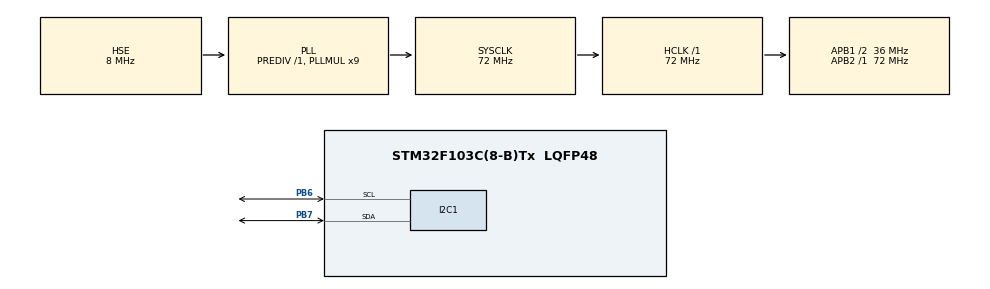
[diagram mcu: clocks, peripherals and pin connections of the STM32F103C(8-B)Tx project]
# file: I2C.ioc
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Mcu.Family=STM32F1
Mcu.Name=STM32F103C(8-B)Tx
Mcu.Package=LQFP48
NVIC.PriorityGroup=NVIC_PRIORITYGROUP_4
PA13.Mode=Serial_Wire
PA13.Signal=SYS_JTMS-SWDIO
PA14.Mode=Serial_Wire
PA14.Signal=SYS_JTCK-SWCLK
PB6.Mode=I2C
PB6.Signal=I2C1_SCL
PB7.Mode=I2C
PB7.Signal=I2C1_SDA
PD0-OSC_IN.Mode=HSE-External-Oscillator
PD0-OSC_IN.Signal=RCC_OSC_IN
PD1-OSC_OUT.Mode=HSE-External-Oscillator
PD1-OSC_OUT.Signal=RCC_OSC_OUT
ProjectManager.HeapSize=0x200
ProjectManager.StackSize=0x400
ProjectManager.TargetToolchain=STM32CubeIDE
RCC.AHBFreq_Value=72000000
RCC.APB1CLKDivider=RCC_HCLK_DIV2
RCC.APB1Freq_Value=36000000
RCC.APB1TimFreq_Value=72000000
RCC.APB2Freq_Value=72000000
RCC.APB2TimFreq_Value=72000000
RCC.HCLKFreq_Value=72000000
RCC.PLLMUL=RCC_PLL_MUL9
RCC.PLLSourceVirtual=RCC_PLLSOURCE_HSE
RCC.SYSCLKFreq_VALUE=72000000
RCC.SYSCLKSource=RCC_SYSCLKSOURCE_PLLCLK
RCC.USBFreq_Value=72000000
board=custom

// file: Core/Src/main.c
/* USER CODE BEGIN Header */
/**
  ******************************************************************************
  * @file           : main.c
  * @brief          : Main program body
  ******************************************************************************
  * @attention
  *
  * Copyright (c) 2025 STMicroelectronics.
  * All rights reserved.
  *
  * This software is licensed under terms that can be found in the LICENSE file
  * in the root directory of this software component.
  * If no LICENSE file comes with this software, it is provided AS-IS.
  *
  ******************************************************************************
  */
/* USER CODE END Header */
#include "main.h"

I2C_HandleTypeDef hi2c1;

void SystemClock_Config(void);
static void MX_GPIO_Init(void);
static void MX_I2C1_Init(void);

/* USER CODE BEGIN 0 */
#define LCD_ADDRESS   (0x27 << 1)
#define LCD_BACKLIGHT 0x08
#define LCD_RS 		  0x01
#define LCD_EN 		  0x04
static void lcd_send_cmd(uint8_t cmd){
	uint8_t data_high, data_low; // tach 4 bit cao 4 bit thap
	uint8_t data_transmit[4];//truyen du lieu 4 bit
	data_high = cmd & 0xF0;
	data_low = (cmd << 4) & 0xF0;

	data_transmit[0] = data_high | LCD_EN | LCD_BACKLIGHT;
	data_transmit[1] = data_high | LCD_BACKLIGHT;
	data_transmit[2] = data_low  | LCD_EN | LCD_BACKLIGHT;
	data_transmit[3] = data_low  | LCD_BACKLIGHT;

	HAL_I2C_Master_Transmit(&hi2c1, LCD_ADDRESS, data_transmit, 4, 100); //bước chốt truyền data xuống lcd
	HAL_Delay(20);
}
static void lcd_send_data(uint8_t data){
	uint8_t data_high, data_low; // tach 4 bit cao 4 bit thap
	uint8_t data_transmit[4];//truyen du lieu 4 bit
	data_high = data & 0xF0;
	data_low = (data << 4) & 0xF0;

	data_transmit[0] = data_high | LCD_EN | LCD_BACKLIGHT | LCD_RS;
	data_transmit[1] = data_high | LCD_BACKLIGHT | LCD_RS;
	data_transmit[2] = data_low  | LCD_EN | LCD_BACKLIGHT | LCD_RS;
	data_transmit[3] = data_low  | LCD_BACKLIGHT | LCD_RS;

	HAL_I2C_Master_Transmit(&hi2c1, LCD_ADDRESS, data_transmit, 4, 100);
	HAL_Delay(20);
}
void lcd_init(){
	HAL_Delay(50);
	lcd_send_cmd(0x30);
	lcd_send_cmd(0x20);
	lcd_send_cmd(0x28);
	lcd_send_cmd(0x08);
	lcd_send_cmd(0x01);
	HAL_Delay(5);
	lcd_send_cmd(0x06);
	lcd_send_cmd(0x0C);
}

void lcd_send_string(char *str){
	while(*str){
		lcd_send_data(*str++);
	}
}
static const uint8_t char_heart[8] = {
	0b00000,
	0b01010,
	0b11111,
	0b11111,
	0b01110,
	0b00100,
	0b00000,
	0b00000
};

void lcd_create_char(uint8_t location, const uint8_t charmap[8]){
	location &=0x07;
	lcd_send_cmd(0x40 | (location << 3));   // set CGRAM addr
		for (uint8_t i = 0; i < 8; i++) {
			lcd_send_data(charmap[i]);
	}
}
static void lcd_set_cursor(uint8_t col, uint8_t row){
    uint8_t addr = (row ? 0x40 : 0x00) + col; // row=0 -> 0x00, row=1 -> 0x40
    lcd_send_cmd(0x80 | addr);                // Set DDRAM address
}

/* USER CODE END 0 */

int main(void)
{

  /* MCU Configuration--------------------------------------------------------*/

  /* Reset of all peripherals, Initializes the Flash interface and the Systick. */
  HAL_Init();

  /* Configure the system clock */
  SystemClock_Config();

  /* Initialize all configured peripherals */
  MX_GPIO_Init();
  MX_I2C1_Init();
  /* USER CODE BEGIN 2 */
  lcd_init();
  lcd_create_char(0, char_heart);
  lcd_set_cursor(0,0);
  //lcd_send_string("kiet an cut");
  lcd_set_cursor(0,1);
  lcd_send_string("I");
  lcd_send_data(0x00);
  lcd_send_string("TikTok");

  /* USER CODE END 2 */

  /* Infinite loop */
  while (1)
  {

  }
}

void SystemClock_Config(void)
{
  RCC_OscInitTypeDef RCC_OscInitStruct = {0};
  RCC_ClkInitTypeDef RCC_ClkInitStruct = {0};

  /** Initializes the RCC Oscillators according to the specified parameters
  * in the RCC_OscInitTypeDef structure.
  */
  RCC_OscInitStruct.OscillatorType = RCC_OSCILLATORTYPE_HSE;
  RCC_OscInitStruct.HSEState = RCC_HSE_ON;
  RCC_OscInitStruct.HSEPredivValue = RCC_HSE_PREDIV_DIV1;
  RCC_OscInitStruct.HSIState = RCC_HSI_ON;
  RCC_OscInitStruct.PLL.PLLState = RCC_PLL_ON;
  RCC_OscInitStruct.PLL.PLLSource = RCC_PLLSOURCE_HSE;
  RCC_OscInitStruct.PLL.PLLMUL = RCC_PLL_MUL9;
  if (HAL_RCC_OscConfig(&RCC_OscInitStruct) != HAL_OK)
  {
    Error_Handler();
  }

  /** Initializes the CPU, AHB and APB buses clocks
  */
  RCC_ClkInitStruct.ClockType = RCC_CLOCKTYPE_HCLK|RCC_CLOCKTYPE_SYSCLK
                              |RCC_CLOCKTYPE_PCLK1|RCC_CLOCKTYPE_PCLK2;
  RCC_ClkInitStruct.SYSCLKSource = RCC_SYSCLKSOURCE_PLLCLK;
  RCC_ClkInitStruct.AHBCLKDivider = RCC_SYSCLK_DIV1;
  RCC_ClkInitStruct.APB1CLKDivider = RCC_HCLK_DIV2;
  RCC_ClkInitStruct.APB2CLKDivider = RCC_HCLK_DIV1;

  if (HAL_RCC_ClockConfig(&RCC_ClkInitStruct, FLASH_LATENCY_2) != HAL_OK)
  {
    Error_Handler();
  }
}

static void MX_I2C1_Init(void)
{

  hi2c1.Instance = I2C1;
  hi2c1.Init.ClockSpeed = 100000;
  hi2c1.Init.DutyCycle = I2C_DUTYCYCLE_2;
  hi2c1.Init.OwnAddress1 = 0;
  hi2c1.Init.AddressingMode = I2C_ADDRESSINGMODE_7BIT;
  hi2c1.Init.DualAddressMode = I2C_DUALADDRESS_DISABLE;
  hi2c1.Init.OwnAddress2 = 0;
  hi2c1.Init.GeneralCallMode = I2C_GENERALCALL_DISABLE;
  hi2c1.Init.NoStretchMode = I2C_NOSTRETCH_DISABLE;
  if (HAL_I2C_Init(&hi2c1) != HAL_OK)
  {
    Error_Handler();
  }

}

static void MX_GPIO_Init(void)
{

  /* GPIO Ports Clock Enable */
  __HAL_RCC_GPIOD_CLK_ENABLE();
  __HAL_RCC_GPIOA_CLK_ENABLE();
  __HAL_RCC_GPIOB_CLK_ENABLE();

}

void Error_Handler(void)
{
  __disable_irq();
  while (1)
  {
  }
}
